# ATmega16HVBrevB device description
Architecture: AVR8; Family: megaAVR
Registers are 8-bit, access not given, no defined reset value unless marked. A register's access mark holds for its fields unless they carry their own. Offsets are from the block's base; [hi:lo] are bit positions; {n}, {i} and the like mark numbered series.

## TWI — Two Wire Serial Interface
Instances: TWI 0x00
0xB8 TWBR — TWI Bit Rate register
  [7:0] TWBR — TWI Bit Rate bits
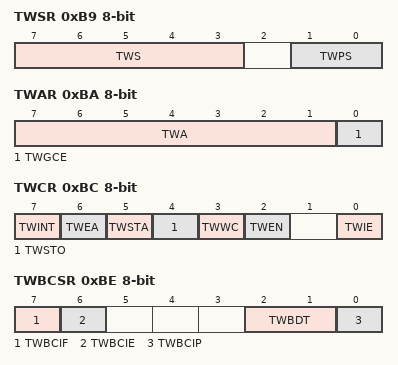
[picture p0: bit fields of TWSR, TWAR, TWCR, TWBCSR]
0xB9 TWSR — TWI Status Register
  [7:3] TWS (bit 3 of the value upward) — TWI Status
  [1:0] TWPS — TWI Prescaler
    0=1; 1=4; 2=16; 3=64
0xBA TWAR — TWI (Slave) Address register
  [7:1] TWA — TWI (Slave) Address register Bits
  [0] TWGCE — TWI General Call Recognition Enable Bit
0xBB TWDR — TWI Data register
  [7:0] TWD — TWI Data Bits
0xBC TWCR — TWI Control Register
  [7] TWINT — TWI Interrupt Flag
  [6] TWEA — TWI Enable Acknowledge Bit
  [5] TWSTA — TWI Start Condition Bit
  [4] TWSTO — TWI Stop Condition Bit
  [3] TWWC — TWI Write Collition Flag
  [2] TWEN — TWI Enable Bit
  [0] TWIE — TWI Interrupt Enable
0xBD TWAMR — TWI (Slave) Address Mask Register
  [7:1] TWAM
0xBE TWBCSR — TWI Bus Control and Status Register
  [7] TWBCIF — TWI Bus Connect/Disconnect Interrupt Flag
  [6] TWBCIE — TWI Bus Connect/Disconnect Interrupt Enable
  [2:1] TWBDT — TWI Bus Disconnect Time-out Period
    0=250ms; 1=500ms; 2=1000ms; 3=2000ms
  [0] TWBCIP — TWI Bus Connect/Disconnect Interrupt Polarity

## EXINT — External Interrupts
Instances: EXINT 0x00
0x3B PCIFR — Pin Change Interrupt Flag Register
  [1:0] PCIF — Pin Change Interrupt Flags
0x3C EIFR — External Interrupt Flag Register
  [3:0] INTF — External Interrupt Flags
0x3D EIMSK — External Interrupt Mask Register
  [3:0] INT — External Interrupt Request 3 Enable
0x68 PCICR — Pin Change Interrupt Control Register
  [1:0] PCIE — Pin Change Interrupt Enables
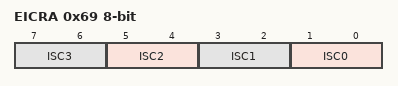
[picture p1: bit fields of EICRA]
0x69 EICRA — External Interrupt Control Register
  [all] fields
    0=Low Level of INTX; 1=Any Logical Change of INTX; 2=Falling Edge of INTX; 3=Rising Edge of INTX
  [2n+1:2n] ISC{n} (n=0..3) — External Interrupt Sense Control {n} Bits
0x6B PCMSK0 — Pin Change Enable Mask Register 0
  [3:0] PCINT — Pin Change Enable Mask
0x6C PCMSK1 — Pin Change Enable Mask Register 1
  [7:0] PCINT (bit 4 of the value upward) — Pin Change Enable Mask

## TC1 (TC16 module) — Timer/Counter, 16-bit
Instances: TC1 0x00
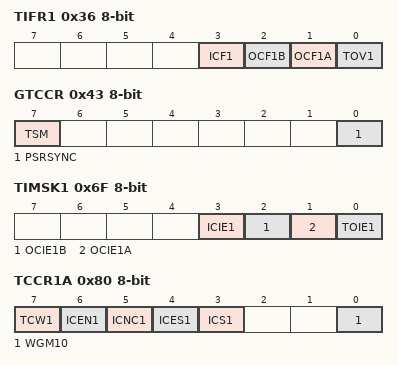
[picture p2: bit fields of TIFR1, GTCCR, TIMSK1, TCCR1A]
0x36 TIFR1 — Timer/Counter Interrupt Flag register
  [3] ICF1 — Timer/Counter 1 Input Capture Flag
  [2] OCF1B — Timer/Counter1 Output Compare Flag B
  [1] OCF1A — Timer/Counter1 Output Compare Flag A
  [0] TOV1 — Timer/Counter1 Overflow Flag
0x43 GTCCR — General Timer/Counter Control Register
  [7] TSM — Timer/Counter Synchronization Mode
  [0] PSRSYNC — Prescaler Reset
0x6F TIMSK1 — Timer/Counter Interrupt Mask Register
  [3] ICIE1 — Timer/Counter n Input Capture Interrupt Enable
  [2] OCIE1B — Timer/Counter1 Output Compare B Interrupt Enable
  [1] OCIE1A — Timer/Counter1 Output Compare A Interrupt Enable
  [0] TOIE1 — Timer/Counter1 Overflow Interrupt Enable
0x80 TCCR1A — Timer/Counter 1 Control Register A
  [7] TCW1 — Timer/Counter Width
  [6] ICEN1 — Input Capture Mode Enable
  [5] ICNC1 — Input Capture Noise Canceler
  [4] ICES1 — Input Capture Edge Select
  [3] ICS1 — Input Capture Select
  [0] WGM10 — Waveform Generation Mode
0x81 TCCR1B — Timer/Counter1 Control Register B
  [2:0] CS (bit 10 of the value upward) — Clock Select1 bis
    0=No Clock Source (Stopped); 1=Running, No Prescaling; 2=Running, CLK/8; 3=Running, CLK/64; 4=Running, CLK/256; 5=Running, CLK/1024; 6=Running, ExtClk Tx Falling Edge; 7=Running, ExtClk Tx Rising Edge
0x84 TCNT1 16-bit — Timer Counter 1 Bytes
  [15:0] TCNT1 — Timer Counter 1 bits
0x88 OCR1A — Output Compare Register 1A
  [7:0] OCR1A — Output Compare 1 A bits
0x89 OCR1B — Output Compare Register B
  [7:0] OCR1B — Output Compare 1 B bits

## TC0 (TC16 module) — Timer/Counter, 16-bit
Instances: TC0 0x00
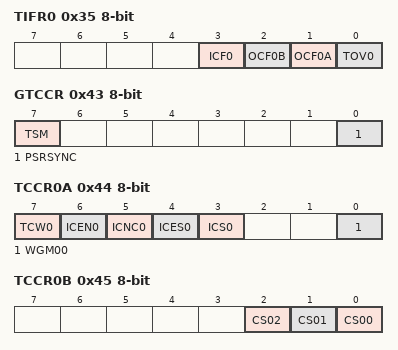
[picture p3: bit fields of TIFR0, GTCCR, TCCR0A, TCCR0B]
0x35 TIFR0 — Timer/Counter Interrupt Flag register
  [3] ICF0 — Timer/Counter 0 Input Capture Flag
  [2] OCF0B — Timer/Counter0 Output Compare Flag B
  [1] OCF0A — Timer/Counter0 Output Compare Flag A
  [0] TOV0 — Timer/Counter0 Overflow Flag
0x43 GTCCR — General Timer/Counter Control Register
  [7] TSM — Timer/Counter Synchronization Mode
  [0] PSRSYNC — Prescaler Reset
0x44 TCCR0A — Timer/Counter 0 Control Register A
  [7] TCW0 — Timer/Counter Width
  [6] ICEN0 — Input Capture Mode Enable
  [5] ICNC0 — Input Capture Noise Canceler
  [4] ICES0 — Input Capture Edge Select
  [3] ICS0 — Input Capture Select
  [0] WGM00 — Waveform Generation Mode
0x45 TCCR0B — Timer/Counter0 Control Register B
  [2] CS02 — Clock Select0 bit 2
  [1] CS01 — Clock Select0 bit 1
  [0] CS00 — Clock Select0 bit 0
    0=No Clock Source (Stopped); 1=Running, No Prescaling; 2=Running, CLK/8; 3=Running, CLK/64; 4=Running, CLK/256; 5=Running, CLK/1024; 6=Running, ExtClk Tx Falling Edge; 7=Running, ExtClk Tx Rising Edge
0x46 TCNT0 16-bit — Timer Counter 0 Bytes
  [15:0] TCNT0 — Timer Counter 0 bits
0x48 OCR0A — Output Compare Register 0A
  [7:0] OCR0A — Output Compare 0 A bits
0x49 OCR0B — Output Compare Register B
  [7:0] OCR0B — Output Compare 0 B bits
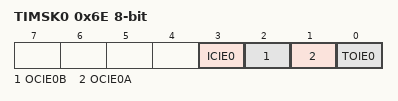
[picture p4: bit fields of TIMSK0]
0x6E TIMSK0 — Timer/Counter Interrupt Mask Register
  [3] ICIE0 — Timer/Counter n Input Capture Interrupt Enable
  [2] OCIE0B — Timer/Counter0 Output Compare B Interrupt Enable
  [1] OCIE0A — Timer/Counter0 Output Compare A Interrupt Enable
  [0] TOIE0 — Timer/Counter0 Overflow Interrupt Enable
